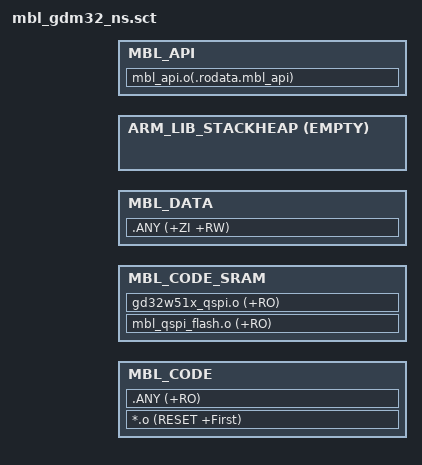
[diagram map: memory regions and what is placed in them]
#! armclang --target=arm-arm-none-eabi -march=armv8-m.main -E -xc -I ../../platform -I ../../../config

/*
 * Copyright (c) 2017-2018 ARM Limited. All rights reserved.
 *
 * Licensed under the Apache License, Version 2.0 (the "License");
 * you may not use this file except in compliance with the License.
 * You may obtain a copy of the License at
 *
 *     http://www.apache.org/licenses/LICENSE-2.0
 *
 * Unless required by applicable law or agreed to in writing, software
 * distributed under the License is distributed on an "AS IS" BASIS,
 * WITHOUT WARRANTIES OR CONDITIONS OF ANY KIND, either express or implied.
 * See the License for the specific language governing permissions and
 * limitations under the License.
 */
#include "mbl_region.h"

LR_CODE_1 MBL_CODE_START MBL_CODE_SIZE {
    MBL_CODE MBL_CODE_START {
        *.o (RESET +First)
        .ANY (+RO)
    }
    MBL_CODE_SRAM MBL_DATA_START {
        mbl_qspi_flash.o (+RO)
        gd32w51x_qspi.o (+RO)
    }
    MBL_DATA +0 ALIGN 16 {
        .ANY (+ZI +RW)
    }
    ARM_LIB_STACKHEAP +0 ALIGN 16 EMPTY MBL_MSP_STACK_SIZE {
    }
}
LR_CODE_2 MBL_API_START MBL_API_SIZE {
    MBL_API MBL_API_START {
        mbl_api.o(.rodata.mbl_api)
    }
}
